# STM32H7B0x register map
File version: 1.3
CPU: CM7 r0p1, little endian, MPU, FPU, 4 interrupt priority bits
Registers are 32-bit, read-write, reset 0x0 unless marked. A register's access mark holds for its fields unless they carry their own. Offsets are from the block's base; [hi:lo] are bit positions; 'fields as' and 'values as' point back to an identical list.

## RCC (part 1 of 3) — Reset and clock control
Base 0x58024400
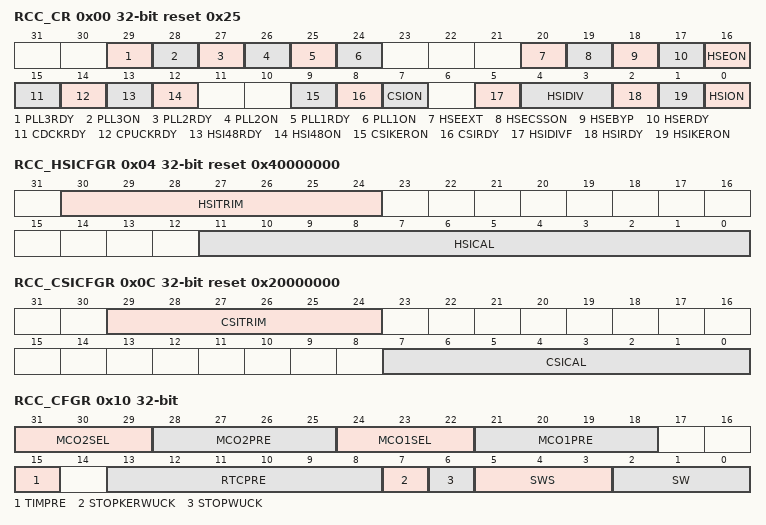
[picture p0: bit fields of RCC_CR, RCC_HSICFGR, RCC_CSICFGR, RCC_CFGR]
0x00 RCC_CR access per field reset 0x25
  [29] PLL3RDY ro — PLL3 clock ready flag Set by hardware to indicate that the PLL3 is locked.
    0=PLL3 unlocked (default after reset); 1=PLL3 locked
  [28] PLL3ON rw — PLL3 enable Set and cleared by software to enable PLL3. Cleared by hardware when entering Stop or Standby mode.
    0=PLL3 OFF (default after reset); 1=PLL3 ON
  [27] PLL2RDY ro — PLL2 clock ready flag Set by hardware to indicate that the PLL2 is locked.
    0=PLL2 unlocked (default after reset); 1=PLL2 locked
  [26] PLL2ON rw — PLL2 enable Set and cleared by software to enable PLL2. Cleared by hardware when entering Stop or Standby mode.
    0=PLL2 OFF (default after reset); 1=PLL2 ON
  [25] PLL1RDY ro — PLL1 clock ready flag Set by hardware to indicate that the PLL1 is locked.
    0=PLL1 unlocked (default after reset); 1=PLL1 locked
  [24] PLL1ON rw — PLL1 enable Set and cleared by software to enable PLL1. Cleared by hardware when entering Stop or Standby mode. Note that the hardware prevents writing this bit to 0, if the PLL1 output is used as the system clock.
    0=PLL1 OFF (default after reset); 1=PLL1 ON
  [20] HSEEXT rw — external high speed clock type in Bypass mode Set and reset by software to select the external clock type (analog or digital). The external clock must be enabled with the HSEON bit to be used by the device. The HSEEXT bit can be written only if the HSE oscillator is disabled.
    0=HSE in analog mode (default after reset); 1=HSE in digital mode
  [19] HSECSSON rw — HSE clock security system enable Set by software to enable clock security system on HSE. This bit is âset onlyâ (disabled by a system reset or when the system enters in Standby mode). When HSECSSON is set, the clock detector is enabled by hardware when the HSE is ready and disabled by hardware if an oscillator failure is detected.
    0=CSS on HSE OFF (clock detector OFF) (default after reset); 1=CSS on HSE ON (clock detector ON if the HSE oscillator is stable, OFF if not)
  [18] HSEBYP rw — HSE clock bypass Set and cleared by software to bypass the oscillator with an external clock. The external clock must be enabled with the HSEON bit to be used by the device. The HSEBYP bit can be written only if the HSE oscillator is disabled.
    0=HSE oscillator not bypassed (default after reset); 1=HSE oscillator bypassed with an external clock
  [17] HSERDY ro — HSE clock ready flag Set by hardware to indicate that the HSE oscillator is stable.
    0=HSE clock is not ready (default after reset); 1=HSE clock is ready
  [16] HSEON rw — HSE clock enable Set and cleared by software. Cleared by hardware to stop the HSE when entering Stop or Standby mode. This bit cannot be cleared if the HSE is used directly (via SW mux) as system clock, or if the HSE is selected as reference clock for PLL1 with PLL1 enabled (PLL1ON bit set to 1).
    0=HSE is OFF (default after reset); 1=HSE is ON
  [15] CDCKRDY ro — CPU domain clocks ready flag Set by hardware to indicate that the following CPU domain clocks are available: APB1, APB2, AHB bus matrix.
    0=CPU domain clocks are not available (default after reset); 1=CPU domain clocks are available
  [14] CPUCKRDY ro — CPU related clocks ready flag Set by hardware to indicate that the CPU related clocks (CPU, APB3, AXI bus matrix and related memories) are available.
    0=CPU related clocks are not available (default after reset); 1=CPU related clocks are available
  [13] HSI48RDY ro — HSI48 clock ready flag Set by hardware to indicate that the HSI48 oscillator is stable.
    0=HSI48 clock is not ready (default after reset); 1=HSI48 clock is ready
  [12] HSI48ON rw — HSI48 clock enable Set by software and cleared by software or by the hardware when the system enters to Stop or Standby mode.
    0=HSI48 is OFF (default after reset); 1=HSI48 is ON
  [9] CSIKERON rw — CSI clock enable in Stop mode Set and reset by software to force the CSI to ON, even in Stop mode, in order to be quickly available as kernel clock for some peripherals. This bit has no effect on the value of CSION.
    0=no effect on CSI (default after reset); 1=CSI is forced to ON even in Stop mode
  [8] CSIRDY ro — CSI clock ready flag Set by hardware to indicate that the CSI oscillator is stable. This bit is activated only if the RC is enabled by CSION (it is not activated if the CSI is enabled by CSIKERON or by a peripheral request).
    0=CSI clock is not ready (default after reset); 1=CSI clock is ready
  [7] CSION rw — CSI clock enable Set and reset by software to enable/disable CSI clock for system and/or peripheral. Set by hardware to force the CSI to ON when the system leaves Stop mode, if STOPWUCK = 1 or STOPKERWUCK = 1. This bit cannot be cleared if the CSI is used directly (via SW mux) as system clock, or if the CSI is selected as reference clock for PLL1 with PLL1 enabled (PLL1ON bit set to 1).
    0=CSI is OFF (default after reset); 1=CSI is ON
  [5] HSIDIVF ro — HSI divider flag Set and reset by hardware. As a write operation to HSIDIV has not an immediate effect on the frequency, this flag indicates the current status of the HSI divider. HSIDIVF goes immediately to 0 when HSIDIV value is changed, and is set back to 1 when the output frequency matches the value programmed into HSIDIV. clock setting is completed)
    0=new division ratio not yet propagated to hsi(_ker)_ck (default after reset); 1=hsi(_ker)_ck clock frequency reflects the new HSIDIV value (default register value when the
  [4:3] HSIDIV rw — HSI clock divider Set and reset by software. These bits allow selecting a division ratio in order to configure the wanted HSI clock frequency. The HSIDIV cannot be changed if the HSI is selected as reference clock for at least one enabled PLL (PLLxON bit set to 1). In that case, the new HSIDIV value is ignored.
    0=division by 1, hsi(_ker)_ck = 64 MHz (default after reset); 1=division by 2, hsi(_ker)_ck = 32 MHz; 2=division by 4, hsi(_ker)_ck = 16 MHz; 3=division by 8, hsi(_ker)_ck = 8 MHz
  [2] HSIRDY ro — HSI clock ready flag Set by hardware to indicate that the HSI oscillator is stable.
    0=HSI clock is not ready (default after reset); 1=HSI clock is ready
  [1] HSIKERON rw — HSI clock enable in Stop mode Set and reset by software to force the HSI to ON, even in Stop mode, in order to be quickly available as kernel clock for peripherals. This bit has no effect on the value of HSION.
    0=no effect on HSI (default after reset); 1=HSI is forced to ON even in Stop mode
  [0] HSION rw — HSI clock enable Set and cleared by software. Set by hardware to force the HSI to ON when the product leaves Stop mode, if STOPWUCK = 0 or STOPKERWUCK = 0. Set by hardware to force the HSI to ON when the product leaves Standby mode or in case of a failure of the HSE which is used as the system clock source. This bit cannot be cleared if the HSI is used directly (via SW mux) as system clock, or if the HSI is selected as reference clock for PLL1 with PLL1 enabled (PLL1ON bit set to 1).
    0=HSI is OFF; 1=HSI is ON (default after reset)
0x04 RCC_HSICFGR access per field reset 0x40000000 (reset mask 0xFFFFF000) — RCC HSI calibration register
  [30:24] HSITRIM rw — HSI clock trimming Set by software to adjust calibration. HSITRIM field is added to the engineering option bytes loaded during reset phase (FLASH_HSI_opt) in order to form the calibration trimming value. HSICALÂ =Â HSITRIMÂ +Â FLASH_HSI_opt. Note: The reset value of the field is 0x40.
  [11:0] HSICAL ro — HSI clock calibration Set by hardware by option byte loading during system reset nreset. Adjusted by software through trimming bits HSITRIM. This field represents the sum of engineering option byte calibration value and HSITRIM bits value.
0x08 RCC_CRRCR ro (reset mask 0xFFFFF000) — RCC clock recovery RC register
  [9:0] HSI48CAL — Internal RC 48 MHz clock calibration Set by hardware by option byte loading during system reset nreset. Read-only.
0x0C RCC_CSICFGR access per field reset 0x20000000 (reset mask 0xFFFFF000) — RCC CSI calibration register
  [29:24] CSITRIM rw — CSI clock trimming Set by software to adjust calibration. CSITRIM field is added to the engineering option bytes loaded during reset phase (FLASH_CSI_opt) in order to form the calibration trimming value. CSICALÂ =Â CSITRIMÂ +Â FLASH_CSI_opt. Note: The reset value of the field is 0x20.
  [7:0] CSICAL ro — CSI clock calibration Set by hardware by option byte loading during system reset nreset. Adjusted by software through trimming bits CSITRIM. This field represents the sum of engineering option byte calibration value and CSITRIM bits value.
0x10 RCC_CFGR access per field
  [31:29] MCO2SEL rw — microcontroller clock output 2 Set and cleared by software. Clock source selection may generate glitches on MCO2. It is highly recommended to configure these bits only after reset, before enabling the external oscillators and the PLLs. others: reserved
    0=system clock selected (sys_ck) (default after reset); 1=PLL2 oscillator clock selected (pll2_p_ck); 2=HSE clock selected (hse_ck); 3=PLL1 clock selected (pll1_p_ck); 4=CSI clock selected (csi_ck); 5=LSI clock selected (lsi_ck)
  [28:25] MCO2PRE rw — MCO2 prescaler Set and cleared by software to configure the prescaler of the MCO2. Modification of this prescaler may generate glitches on MCO2. It is highly recommended to change this prescaler only after reset, before enabling the external oscillators and the PLLs. ...
    0=prescaler disabled (default after reset); 1=division by 1 (bypass); 2=division by 2; 3=division by 3; 4=division by 4; 15=division by 15
  [24:22] MCO1SEL rw — Microcontroller clock output 1 Set and cleared by software. Clock source selection may generate glitches on MCO1. It is highly recommended to configure these bits only after reset, before enabling the external oscillators and the PLLs. others: reserved
    0=HSI clock selected (hsi_ck) (default after reset); 1=LSE oscillator clock selected (lse_ck); 2=HSE clock selected (hse_ck); 3=PLL1 clock selected (pll1_q_ck); 4=HSI48 clock selected (hsi48_ck)
  [21:18] MCO1PRE rw — MCO1 prescaler Set and cleared by software to configure the prescaler of the MCO1. Modification of this prescaler may generate glitches on MCO1. It is highly recommended to change this prescaler only after reset, before enabling the external oscillators and the PLLs. ...
    values as MCO2PRE
  [15] TIMPRE rw — timers clocks prescaler selection This bit is set and reset by software to control the clock frequency of all the timers connected to APB1 and APB2 domains. Refer to for more details.
    0=The timers kernel clock is equal to rcc_hclk1 if CDPPRE1 or CDPPRE2 corresponds to a division by 1 or 2, else it is equal to 2 x Frcc_pclk1 or 2 x Frcc_pclk2 (default after reset); 1=The timers kernel clock is equal to 2 x Frcc_pclk1 or 2 x Frcc_pclk2 if CDPPRE1 or CDPPRE2 corresponds to a division by 1, 2or 4, else it is equal to 4 x Frcc_pclk1 or 4 x Frcc_pclk2
  [13:8] RTCPRE rw — HSE division factor for RTC clock Set and cleared by software to divide the HSE to generate a clock for RTC. Caution: The software must set these bits correctly to ensure that the clock supplied to the RTC is lower than 1Â MHz. These bits must be configured if needed before selecting the RTC clock source. ...
    0=no clock (default after reset); 1=no clock; 2=HSE/2; 3=HSE/3; 4=HSE/4; 62=HSE/62; 63=HSE/63
  [7] STOPKERWUCK rw — kernel clock selection after a wake up from system Stop Set and reset by software to select the kernel wakeup clock from system Stop. See for details.
    0=HSI selected as wake up clock from system Stop (default after reset); 1=CSI selected as wake up clock from system Stop
  [6] STOPWUCK rw — system clock selection after a wake up from system Stop Set and reset by software to select the system wakeup clock from system Stop. The selected clock is also used as emergency clock for the clock security system (CSS) on HSE. See for details. STOPWUCK must not be modified when CSS is enabled (by HSECSSON bit) and the system clock is HSE (SWSÂ =Â 10) or a switch on HSE is requested (SWÂ =10).
    values as STOPKERWUCK
  [5:3] SWS ro — system clock switch status Set and reset by hardware to indicate which clock source is used as system clock. others: reserved
    0=HSI used as system clock (hsi_ck) (default after reset); 1=CSI used as system clock (csi_ck); 2=HSE used as system clock (hse_ck); 3=PLL1 used as system clock (pll1_p_ck)
  [2:0] SW rw — system clock and trace clock switch Set and reset by software to select system clock and trace clock sources (sys_ck and traceclk). Set by hardware in order to: force the selection of the HSI or CSI (depending on STOPWUCK selection) when leaving a system Stop mode force the selection of the HSI in case of failure of the HSE when used directly or indirectly as system clock others: reserved
    0=HSI selected as system clock (hsi_ck) (default after reset); 1=CSI selected as system clock (csi_ck); 2=HSE selected as system clock (hse_ck); 3=PLL1 selected as system clock (pll1_p_ck for sys_ck, pll1_r_ck for traceclk)
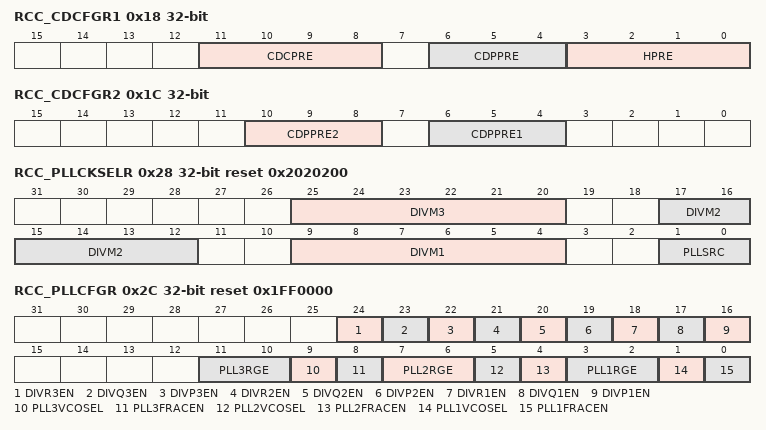
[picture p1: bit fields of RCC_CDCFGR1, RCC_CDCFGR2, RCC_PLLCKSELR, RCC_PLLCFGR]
0x18 RCC_CDCFGR1
  [11:8] CDCPRE — CPU domain core prescaler Set and reset by software to control the CPU domain CPU clock division factor. Changing this division ratio has an impact on the frequency of the CPU clock and all bus matrix clocks. After changing this prescaler value, it takes up to 16 periods of the slowest APB clock before the new division ratio is taken into account. The application can check if the new division factor is taken into account by reading back this register. 0xxx: sys_ck not divided (default after reset)
    8=sys_ck divided by 2; 9=sys_ck divided by 4; 10=sys_ck divided by 8; 11=sys_ck divided by 16; 12=sys_ck divided by 64; 13=sys_ck divided by 128; 14=sys_ck divided by 256; 15=sys_ck divided by 512
  [6:4] CDPPRE — CPU domain APB3 prescaler Set and reset by software to control the division factor of rcc_pclk3. The clock is divided by the new prescaler factor from 1 to 16 cycles of rcc_hclk3 after CDPPRE write. 0xx: rcc_pclk3 = rcc_hclk3 (default after reset)
    4=rcc_pclk3 = rcc_hclk3 / 2; 5=rcc_pclk3 = rcc_hclk3 / 4; 6=rcc_pclk3 = rcc_hclk3 / 8; 7=rcc_pclk3 = rcc_hclk3 / 16
  [3:0] HPRE — CPU domain AHB prescaler Set and reset by software to control the division factor of rcc_hclk3 and rcc_aclk. Changing this division ratio has an impact on the frequency of all bus matrix clocks. 0xxx: rcc_hclk3 = sys_cdcpre_ck (default after reset) Note: The clocks are divided by the new prescaler factor from1 to 16 periods of the slowest APB clock among rcc_pclk[4:1] after HPRE update. Note: Note also that rcc_hclk3 = rcc_aclk.
    8=rcc_hclk3 = sys_cdcpre_ck / 2; 9=rcc_hclk3 = sys_cdcpre_ck / 4; 10=rcc_hclk3 = sys_cdcpre_ck / 8; 11=rcc_hclk3 = sys_cdcpre_ck / 16; 12=rcc_hclk3 = sys_cdcpre_ck / 64; 13=rcc_hclk3 = sys_cdcpre_ck / 128; 14=rcc_hclk3 = sys_cdcpre_ck / 256; 15=rcc_hclk3 = sys_cdcpre_ck / 512
0x1C RCC_CDCFGR2
  [10:8] CDPPRE2 — CPU domain APB2 prescaler Set and reset by software to control the CPU domain APB2 clock division factor. The clock is divided by the new prescaler factor from 1 to 16 cycles of rcc_hclk1 after CDPPRE2 write. 0xx: rcc_pclk2 = rcc_hclk1 (default after reset)
    4=rcc_pclk2 = rcc_hclk1 / 2; 5=rcc_pclk2 = rcc_hclk1 / 4; 6=rcc_pclk2 = rcc_hclk1 / 8; 7=rcc_pclk2 = rcc_hclk1 / 16
  [6:4] CDPPRE1 — CPU domain APB1 prescaler Set and reset by software to control the CPU domain APB1 clock division factor. The clock is divided by the new prescaler factor from 1 to 16 cycles of rcc_hclk1 after CDPPRE1 write. 0xx: rcc_pclk1 = rcc_hclk1 (default after reset)
    4=rcc_pclk1 = rcc_hclk1 / 2; 5=rcc_pclk1 = rcc_hclk1 / 4; 6=rcc_pclk1 = rcc_hclk1 / 8; 7=rcc_pclk1 = rcc_hclk1 / 16
0x20 RCC_SRDCFGR
  [6:4] SRDPPRE — SmartRun domain APB4 prescaler Set and reset by software to control the SmartRun domain APB4 clock division factor. The clock is divided by the new prescaler factor from 1 to 16 cycles of rcc_hclk4 after SRDPPRE write. 0xx: rcc_pclk4 = rcc_hclk4 (default after reset)
    4=rcc_pclk4 = rcc_hclk4 / 2; 5=rcc_pclk4 = rcc_hclk4 / 4; 6=rcc_pclk4 = rcc_hclk4 / 8; 7=rcc_pclk4 = rcc_hclk4 / 16
0x28 RCC_PLLCKSELR reset 0x2020200
  [25:20] DIVM3 — prescaler for PLL3 Set and cleared by software to configure the prescaler of the PLL3. The hardware does not allow any modification of this prescaler when PLL3 is enabled (PLL3ONÂ =Â 1). In order to save power when PLL3 is not used, the value of DIVM3 must be set to 0. ... ...
    0=prescaler disabled (default after reset); 1=division by 1 (bypass); 2=division by 2; 3=division by 3; 32=division by 32 (default after reset); 63=division by 63
  [17:12] DIVM2 — prescaler for PLL2 Set and cleared by software to configure the prescaler of the PLL2. The hardware does not allow any modification of this prescaler when PLL2 is enabled (PLL2ONÂ =Â 1). In order to save power when PLL2 is not used, the value of DIVM2 must be set to 0. ... ...
    0=prescaler disabled; 1=division by 1 (bypass); 2=division by 2; 3=division by 3; 32=division by 32 (default after reset); 63=division by 63
  [9:4] DIVM1 — prescaler for PLL1 Set and cleared by software to configure the prescaler of the PLL1. The hardware does not allow any modification of this prescaler when PLL1 is enabled (PLL1ONÂ =Â 1). In order to save power when PLL1 is not used, the value of DIVM1 must be set to 0. ... ...
    values as DIVM2
  [1:0] PLLSRC — DIVMx and PLLs clock source selection Set and reset by software to select the PLL clock source. These bits can be written only when all PLLs are disabled. In order to save power, when no PLL is used, the value of PLLSRC must be set to '11â.
    0=HSI selected as PLL clock (hsi_ck) (default after reset); 1=CSI selected as PLL clock (csi_ck); 2=HSE selected as PLL clock (hse_ck); 3=no clock send to DIVMx divider and PLLs
0x2C RCC_PLLCFGR reset 0x1FF0000
  [24] DIVR3EN — PLL3 DIVR divider output enable Set and reset by software to enable the pll3_r_ck output of the PLL3. To save power, DIVR3EN and DIVR3 bits must be set to 0 when the pll3_r_ck is not used. This bit can be written only when the PLL3 is disabled (PLL3ON = 0 and PLL3RDY = 0).
    0=pll3_r_ck output disabled; 1=pll3_r_ck output enabled (default after reset)
  [23] DIVQ3EN — PLL3 DIVQ divider output enable Set and reset by software to enable the pll3_q_ck output of the PLL3. To save power, DIVR3EN and DIVR3 bits must be set to 0 when the pll3_r_ck is not used. This bit can be written only when the PLL3 is disabled (PLL3ON = 0 and PLL3RDY = 0).
    0=pll3_q_ck output disabled; 1=pll3_q_ck output enabled (default after reset)
  [22] DIVP3EN — PLL3 DIVP divider output enable Set and reset by software to enable the pll3_p_ck output of the PLL3. This bit can be written only when the PLL3 is disabled (PLL3ON = 0 and PLL3RDY = 0). To save power, DIVR3EN and DIVR3 bits must be set to 0 when the pll3_r_ck is not used.
    0=pll3_p_ck output disabled; 1=pll3_p_ck output enabled (default after reset)
  [21] DIVR2EN — PLL2 DIVR divider output enable Set and reset by software to enable the pll2_r_ck output of the PLL2. To save power, DIVR3EN and DIVR3 bits must be set to 0 when the pll3_r_ck is not used. This bit can be written only when the PLL2 is disabled (PLL2ON = 0 and PLL2RDY = 0).
    0=pll2_r_ck output disabled; 1=pll2_r_ck output enabled (default after reset)
  [20] DIVQ2EN — PLL2 DIVQ divider output enable Set and reset by software to enable the pll2_q_ck output of the PLL2. To save power, DIVR3EN and DIVR3 bits must be set to 0 when the pll3_r_ck is not used. This bit can be written only when the PLL2 is disabled (PLL2ON = 0 and PLL2RDY = 0).
    0=pll2_q_ck output disabled; 1=pll2_q_ck output enabled (default after reset)
  [19] DIVP2EN — PLL2 DIVP divider output enable Set and reset by software to enable the pll2_p_ck output of the PLL2. This bit can be written only when the PLL2 is disabled (PLL2ON = 0 and PLL2RDY = 0). To save power, DIVR3EN and DIVR3 bits must be set to 0 when the pll3_r_ck is not used.
    0=pll2_p_ck output disabled; 1=pll2_p_ck output enabled (default after reset)
  [18] DIVR1EN — PLL1 DIVR divider output enable Set and reset by software to enable the pll1_r_ck output of the PLL1. To save power, DIVR3EN and DIVR3 bits must be set to 0 when the pll3_r_ck is not used. This bit can be written only when the PLL1 is disabled (PLL1ON = 0 and PLL1RDY = 0).
    0=pll1_r_ck output disabled; 1=pll1_r_ck output enabled (default after reset)
  [17] DIVQ1EN — PLL1 DIVQ divider output enable Set and reset by software to enable the pll1_q_ck output of the PLL1. In order to save power, when the pll1_q_ck output of the PLL1 is not used, the pll1_q_ck must be disabled. This bit can be written only when the PLL1 is disabled (PLL1ON = 0 and PLL1RDY = 0).
    0=pll1_q_ck output disabled; 1=pll1_q_ck output enabled (default after reset)
  [16] DIVP1EN — PLL1 DIVP divider output enable Set and reset by software to enable the pll1_p_ck output of the PLL1. This bit can be written only when the PLL1 is disabled (PLL1ON = 0 and PLL1RDY = 0). In order to save power, when the pll1_p_ck output of the PLL1 is not used, the pll1_p_ck must be disabled.
    0=pll1_p_ck output disabled; 1=pll1_p_ck output enabled (default after reset)
  [11:10] PLL3RGE — PLL3 input frequency range Set and reset by software to select the proper reference frequency range used for PLL3. These bits must be written before enabling the PLL3.
    0=PLL3 input (ref3_ck) clock range frequency between 1 and 2 MHz (default after reset); 1=PLL3 input (ref3_ck) clock range frequency between 2 and 4 MHz; 2=PLL3 input (ref3_ck) clock range frequency between 4 and 8 MHz; 3=PLL3 input (ref3_ck) clock range frequency between 8 and 16 MHz
  [9] PLL3VCOSEL — PLL3 VCO selection Set and reset by software to select the proper VCO frequency range used for PLL3. This bit must be written before enabling the PLL3.
    0=wide VCO range 128 to 560 MHz (default after reset); 1=medium VCO range 150 to 420 MHz
  [8] PLL3FRACEN — PLL3 fractional latch enable Set and reset by software to latch the content of FRACN3 into the sigma-delta modulator. In order to latch the FRACN3 value into the sigma-delta modulator, PLL3FRACEN must be set to 0, then set to 1. The transition 0 to 1 transfers the content of FRACN3 into the modulator. Refer to for additional information.
  [7:6] PLL2RGE — PLL2 input frequency range Set and reset by software to select the proper reference frequency range used for PLL2. These bits must be written before enabling the PLL2.
    0=PLL2 input (ref2_ck) clock range frequency between 1 and 2 MHz (default after reset); 1=PLL2 input (ref2_ck) clock range frequency between 2 and 4 MHz; 2=PLL2 input (ref2_ck) clock range frequency between 4 and 8 MHz; 3=PLL2 input (ref2_ck) clock range frequency between 8 and 16 MHz
  [5] PLL2VCOSEL — PLL2 VCO selection Set and reset by software to select the proper VCO frequency range used for PLL2. This bit must be written before enabling the PLL2.
    values as PLL3VCOSEL
  [4] PLL2FRACEN — PLL2 fractional latch enable Set and reset by software to latch the content of FRACN2 into the sigma-delta modulator. In order to latch the FRACN2 value into the sigma-delta modulator, PLL2FRACEN must be set to 0, then set to 1. The transition 0 to 1 transfers the content of FRACN2 into the modulator. Refer to for additional information.
  [3:2] PLL1RGE — PLL1 input frequency range Set and reset by software to select the proper reference frequency range used for PLL1. This bit must be written before enabling the PLL1.
    0=PLL1 input (ref1_ck) clock range frequency between 1 and 2 MHz (default after reset); 1=PLL1 input (ref1_ck) clock range frequency between 2 and 4 MHz; 2=PLL1 input (ref1_ck) clock range frequency between 4 and 8 MHz; 3=PLL1 input (ref1_ck) clock range frequency between 8 and 16 MHz
  [1] PLL1VCOSEL — PLL1 VCO selection Set and reset by software to select the proper VCO frequency range used for PLL1. These bits must be written before enabling the PLL1.
    0=wide VCO range from 128 to 560 MHz (default after reset); 1=medium VCO range from 150 to 420 MHz
  [0] PLL1FRACEN — PLL1 fractional latch enable Set and reset by software to latch the content of FRACN1 into the sigma-delta modulator. In order to latch the FRACN1 value into the sigma-delta modulator, PLL1FRACEN must be set to 0, then set to 1. The transition 0 to 1 transfers the content of FRACN1 into the modulator. Refer to for additional information.
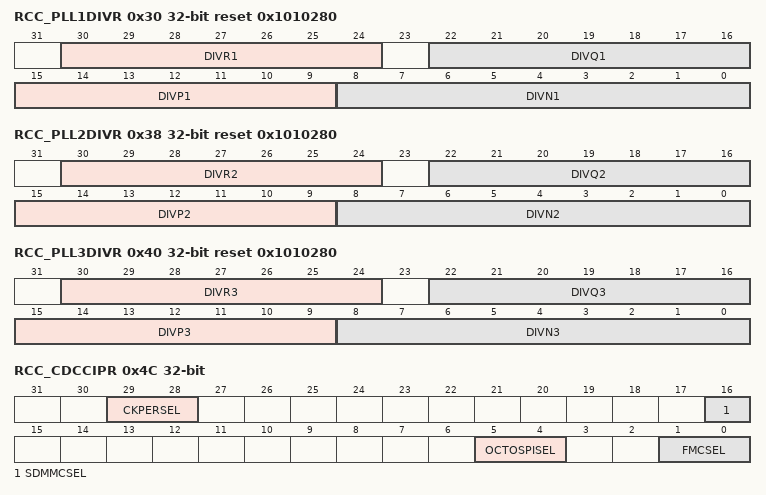
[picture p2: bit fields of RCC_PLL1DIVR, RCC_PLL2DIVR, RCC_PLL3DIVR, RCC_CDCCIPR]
0x30 RCC_PLL1DIVR reset 0x1010280
  [30:24] DIVR1 — PLL1 DIVR division factor Set and reset by software to control the frequency of the pll1_r_ck clock. These bits can be written only when the PLL1 is disabled (PLL1ON = 0 and PLL1RDY = 0). ...
    0=pll1_r_ck = vco1_ck; 1=pll1_r_ck = vco1_ck / 2 (default after reset); 2=pll1_r_ck = vco1_ck / 3; 3=pll1_r_ck = vco1_ck / 4; 127=pll1_r_ck = vco1_ck / 128
  [22:16] DIVQ1 — PLL1 DIVQ division factor Set and reset by software to control the frequency of the pll1_q_ck clock. These bits can be written only when the PLL1 is disabled (PLL1ON = 0 and PLL1RDY = 0). ...
    0=pll1_q_ck = vco1_ck; 1=pll1_q_ck = vco1_ck / 2 (default after reset); 2=pll1_q_ck = vco1_ck / 3; 3=pll1_q_ck = vco1_ck / 4; 127=pll1_q_ck = vco1_ck / 128
  [15:9] DIVP1 — PLL1 DIVP division factor Set and reset by software to control the frequency of the pll1_p_ck clock. These bits can be written only when the PLL1 is disabled (PLL1ON = 0 and PLL1RDY = 0). Note that odd division factors are not allowed. ...
    0=not allowed; 1=pll1_p_ck = vco1_ck / 2 (default after reset); 2=not allowed; 3=pll1_p_ck = vco1_ck / 4; 127=pll1_p_ck = vco1_ck / 128
  [8:0] DIVN1 — multiplication factor for PLL1 VCO Set and reset by software to control the multiplication factor of the VCO. These bits can be written only when the PLL is disabled (PLL1ON = PLL1RDY = 0). ..........: not used ... ... Others: wrong configurations The software must set correctly these bits to insure that the VCO output frequency is between its valid frequency range, that is: 128 to 560Â MHz if PLL1VCOSEL = 0 150 to 420Â MHz if PLL1VCOSEL = 1 VCO output frequency = Fref1_ck x DIVN1, when fractional value 0 has been loaded into FRACN1, with: DIVN1 between 8 and 420 The input frequency Fref1_ck must be between 1 and 16Â MHz.
    6=wrong configuration; 7=DIVN1 = 8; 128=DIVN1 = 129 (default after reset); 0x1A3=DIVN1 = 420
0x34 RCC_PLL1FRACR
  [15:3] FRACN1 — fractional part of the multiplication factor for PLL1 VCO Set and reset by software to control the fractional part of the multiplication factor of the VCO. These bits can be written at any time, allowing dynamic fine-tuning of the PLL1 VCO. The software must set correctly these bits to insure that the VCO output frequency is between its valid frequency range, that is: 128 to 560Â MHz if PLL1VCOSEL = 0 150 to 420Â MHz if PLL1VCOSEL = 1 VCO output frequency = Fref1_ck x (DIVN1 + (FRACN1 / 213)), with DIVN1 between 8 and 420 FRACN1 can be between 0 and 213- 1 The input frequency Fref1_ck must be between 1 and 16 MHz. To change the FRACN value on-the-fly even if the PLL is enabled, the application must proceed as follows: Set the bit PLL1FRACEN to 0. Write the new fractional value into FRACN1. Set the bit PLL1FRACEN to 1.
0x38 RCC_PLL2DIVR reset 0x1010280
  [30:24] DIVR2 — PLL2 DIVR division factor Set and reset by software to control the frequency of the pll2_r_ck clock. These bits can be written only when the PLL2 is disabled (PLL2ON = PLL2RDY = 0). ...
    0=pll2_r_ck = vco2_ck; 1=pll2_r_ck = vco2_ck / 2 (default after reset); 2=pll2_r_ck = vco2_ck / 3; 3=pll2_r_ck = vco2_ck / 4; 127=pll2_r_ck = vco2_ck / 128
  [22:16] DIVQ2 — PLL2 DIVQ division factor Set and reset by software to control the frequency of the pll2_q_ck clock. These bits can be written only when the PLL2 is disabled (PLL2ON = PLL2RDY = 0). ...
    0=pll2_q_ck = vco2_ck; 1=pll2_q_ck = vco2_ck / 2 (default after reset); 2=pll2_q_ck = vco2_ck / 3; 3=pll2_q_ck = vco2_ck / 4; 127=pll2_q_ck = vco2_ck / 128
  [15:9] DIVP2 — PLL2 DIVP division factor Set and reset by software to control the frequency of the pll2_p_ck clock. These bits can be written only when the PLL2 is disabled (PLL2ON = PLL2RDY = 0). ...
    0=pll2_p_ck = vco2_ck; 1=pll2_p_ck = vco2_ck / 2 (default after reset); 2=pll2_p_ck = vco2_ck / 3; 3=pll2_p_ck = vco2_ck / 4; 127=pll2_p_ck = vco2_ck / 128
  [8:0] DIVN2 — multiplication factor for PLL2 VCO Set and reset by software to control the multiplication factor of the VCO. These bits can be written only when the PLL is disabled (PLL2ON = PLL2RDY = 0). ..........: not used ... ... Others: wrong configurations The software must set correctly these bits to insure that the VCO output frequency is between its valid frequency range, that is: 128 to 560Â MHz if PLL2VCOSEL = 0 150 to 420Â MHz if PLL2VCOSEL = 1 VCO output frequency = Fref2_ck x DIVN2, when fractional value 0 has been loaded into FRACN2, with DIVN2 between 8 and 420 The input frequency Fref2_ck must be between 1 and 16MHz.
    6=wrong configuration; 7=DIVN2 = 8; 128=DIVN2 = 129 (default after reset); 0x1A3=DIVN2 = 420
0x3C RCC_PLL2FRACR
  [15:3] FRACN2 — fractional part of the multiplication factor for PLL2 VCO Set and reset by software to control the fractional part of the multiplication factor of the VCO. These bits can be written at any time, allowing dynamic fine-tuning of the PLL2 VCO. The software must set correctly these bits to insure that the VCO output frequency is between its valid frequency range, that is: 128 to 560Â MHz if PLL2VCOSEL = 0 150 to 420Â MHz if PLL2VCOSEL = 1 VCO output frequency = Fref2_ck x (DIVN2 + (FRACN2 / 213)), with DIVN2 between 8 and 420 FRACN2 can be between 0 and 213 - 1 The input frequency Fref2_ck must be between 1 and 16 MHz. In order to change the FRACN value on-the-fly even if the PLL is enabled, the application must proceed as follows: Set the bit PLL2FRACEN to 0. Write the new fractional value into FRACN2. Set the bit PLL2FRACEN to 1.
0x40 RCC_PLL3DIVR reset 0x1010280
  [30:24] DIVR3 — PLL3 DIVR division factor Set and reset by software to control the frequency of the pll3_r_ck clock. These bits can be written only when the PLL3 is disabled (PLL3ON = PLL3RDY = 0). ...
    0=pll3_r_ck = vco3_ck; 1=pll3_r_ck = vco3_ck / 2 (default after reset); 2=pll3_r_ck = vco3_ck / 3; 3=pll3_r_ck = vco3_ck / 4; 127=pll3_r_ck = vco3_ck / 128
  [22:16] DIVQ3 — PLL3 DIVQ division factor Set and reset by software to control the frequency of the pll3_q_ck clock. These bits can be written only when the PLL3 is disabled (PLL3ON = PLL3RDY = 0). ...
    0=pll3_q_ck = vco3_ck; 1=pll3_q_ck = vco3_ck / 2 (default after reset); 2=pll3_q_ck = vco3_ck / 3; 3=pll3_q_ck = vco3_ck / 4; 127=pll3_q_ck = vco3_ck / 128
  [15:9] DIVP3 — PLL3 DIVP division factor Set and reset by software to control the frequency of the pll3_p_ck clock. These bits can be written only when the PLL3 is disabled (PLL3ON = PLL3RDY = 0). ...
    0=pll3_p_ck = vco3_ck; 1=pll3_p_ck = vco3_ck / 2 (default after reset); 2=pll3_p_ck = vco3_ck / 3; 3=pll3_p_ck = vco3_ck / 4; 127=pll3_p_ck = vco3_ck / 128
  [8:0] DIVN3 — Multiplication factor for PLL3 VCO Set and reset by software to control the multiplication factor of the VCO. These bits can be written only when the PLL is disabled (PLL3ON = PLL3RDY = 0). ...........: not used ... ... Others: wrong configurations The software must set correctly these bits to insure that the VCO output frequency is between its valid frequency range, that is: 128 to 560Â MHz if PLL3VCOSEL = 0 150 to 420Â MHz if PLL3VCOSEL = 1 VCO output frequency = Fref3_ck x DIVN3, when fractional value 0 has been loaded into FRACN3, with: DIVN3 between 8 and 420 The input frequency Fref3_ck must be between 1 and 16MHz
    6=wrong configuration; 7=DIVN3 = 8; 128=DIVN3 = 129 (default after reset); 0x1A3=DIVN3 = 420
0x44 RCC_PLL3FRACR
  [15:3] FRACN3 — fractional part of the multiplication factor for PLL3 VCO Set and reset by software to control the fractional part of the multiplication factor of the VCO. These bits can be written at any time, allowing dynamic fine-tuning of the PLL3 VCO. The software must set correctly these bits to insure that the VCO output frequency is between its valid frequency range, that is: 128 to 560Â MHz if PLL3VCOSEL = 0 150 to 420Â MHz if PLL3VCOSEL = 1 VCO output frequency = Fref3_ck x (DIVN3 + (FRACN3 / 213)), with DIVN3 between 8 and 420 FRACN3 can be between 0 and 213 - 1 The input frequency Fref3_ck must be between 1 and 16 MHz. In order to change the FRACN value on-the-fly even if the PLL is enabled, the application must proceed as follows: Set the bit PLL1FRACEN to 0. Write the new fractional value into FRACN1. Set the bit PLL1FRACEN to 1.
0x4C RCC_CDCCIPR — RCC CPU domain kernel clock configuration register
  [29:28] CKPERSEL — per_ck clock source selection
    0=hsi_ker_ck selected as per_ck clock (default after reset); 1=csi_ker_ck selected as per_ck clock; 2=hse_ck selected as per_ck clock; 3=reserved, the per_ck clock is disabled
  [16] SDMMCSEL — SDMMC kernel clock source selection
    0=pll1_q_ck selected as kernel peripheral clock (default after reset); 1=pll2_r_ck selected as kernel peripheral clock
  [5:4] OCTOSPISEL — OCTOSPI kernel clock source selection
    0=rcc_hclk3 selected as kernel peripheral clock (default after reset); 1=pll1_q_ck selected as kernel peripheral clock; 2=pll2_r_ck selected as kernel peripheral clock; 3=per_ck selected as kernel peripheral clock
  [1:0] FMCSEL — FMC kernel clock source selection
    values as OCTOSPISEL
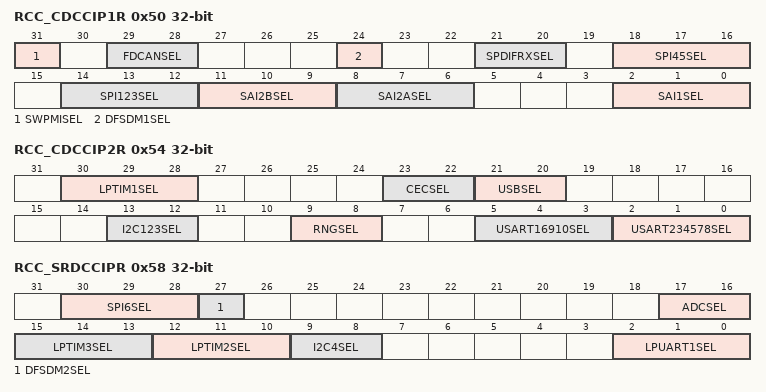
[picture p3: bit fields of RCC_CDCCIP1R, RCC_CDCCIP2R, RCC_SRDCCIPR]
0x50 RCC_CDCCIP1R — RCC CPU domain kernel clock configuration register
  [31] SWPMISEL — SWPMI kernel clock source selection Set and reset by software.
    0=rcc_pclk1 selected as SWPMI kernel clock (default after reset); 1=hsi_ker_ck selected as SWPMI kernel clock
  [29:28] FDCANSEL — FDCAN kernel clock source selection Set and reset by software.
    0=hse_ck clock selected as FDCAN kernel clock (default after reset); 1=pll1_q_ck selected as FDCAN kernel clock; 2=pll2_q_ck selected as FDCAN kernel clock; 3=reserved, the kernel clock is disabled
  [24] DFSDM1SEL — DFSDM1 kernel clock Clk source selection Set and reset by software. Note: the DFSDM1 Aclk clock source selection is done by SAI1SEL (see ).
    0=rcc_pclk2 selected as DFSDM1 Clk kernel clock (default after reset); 1=sys_ck selected as DFSDM1 Clk kernel clock
  [21:20] SPDIFRXSEL — SPDIFRX kernel clock source selection
    0=pll1_q_ck selected as SPDIFRX kernel clock (default after reset); 1=pll2_r_ck selected as SPDIFRX kernel clock; 2=pll3_r_ck selected as SPDIFRX kernel clock; 3=hsi_ker_ck selected as SPDIFRX kernel clock
  [18:16] SPI45SEL — SPI4 and 5 kernel clock source selection Set and reset by software. others: reserved, the kernel clock is disabled
    0=rcc_pclk2 clock selected as kernel clock (default after reset); 1=pll2_q_ck is selected as kernel clock; 2=pll3_q_ck is selected as kernel clock; 3=hsi_ker_ck is selected as kernel clock; 4=csi_ker_ck is selected as kernel clock; 5=hse_ck is selected as kernel clock
  [14:12] SPI123SEL — SPI/I2S1,2 and 3 kernel clock source selection Set and reset by software. If the selected clock is the external clock and this clock is stopped, it is not be possible to switch to another clock. Refer to for additional information. others: reserved, the kernel clock is disabled Note: I2S_CKIN is an external clock taken from a pin.
    0=pll1_q_ck selected as SPI/I2S1,2 and 3 kernel clock (default after reset); 1=pll2_p_ck selected as SPI/I2S1,2 and 3 kernel clock; 2=pll3_p_ck selected as SPI/I2S1,2 and 3 kernel clock; 3=I2S_CKIN selected as SPI/I2S1,2 and 3 kernel clock; 4=per_ck selected as SPI/I2S1,2 and 3 kernel clock
  [11:9] SAI2BSEL — SAI2 kernel clock B source selection Set and reset by software. If the selected clock is the external clock and this clock is stopped, it is not be possible to switch to another clock. Refer to for additional information. others: reserved, the kernel clock is disabled Note: I2S_CKIN is an external clock taken from a pin. spdifrx_symb_ck is the symbol clock generated by the spdifrx (see ).
    0=pll1_q_ck selected as SAI2 kernel clock B (default after reset); 1=pll2_p_ck selected as SAI2 kernel clock B; 2=pll3_p_ck selected as SAI2 kernel clock B; 3=I2S_CKIN selected as SAI2 kernel clock B; 4=per_ck selected as SAI2 kernel clock B; 5=spdifrx_symb_ck selected as SAI2 kernel clock B
  [8:6] SAI2ASEL — SAI2 kernel clock source A selection Set and reset by software. If the selected clock is the external clock and this clock is stopped, it is not be possible to switch to another clock. Refer to for additional information. others: reserved, the kernel clock is disabled Note: I2S_CKIN is an external clock taken from a pin. spdifrx_symb_ck is the symbol clock generated by the SPDIFRX (see ).
    0=pll1_q_ck selected as SAI2 kernel clock A (default after reset); 1=pll2_p_ck selected as SAI2 kernel clock A; 2=pll3_p_ck selected as SAI2 kernel clock A; 3=I2S_CKIN selected as SAI2 kernel clock A; 4=per_ck selected as SAI2 kernel clock A; 5=spdifrx_symb_ck selected as SAI2 kernel clock A
  [2:0] SAI1SEL — SAI1 and DFSDM1 kernel Aclk clock source selection Set and reset by software. If the selected clock is the external clock and this clock is stopped, it isnot be possible to switch to another clock. Refer to for additional information. Note: DFSDM1 clock source selection is done by DFSDM1SEL. others: reserved, the kernel clock is disabled Note: I2S_CKIN is an external clock taken from a pin.
    0=pll1_q_ck selected as SAI1 and DFSDM1 Aclk kernel clock (default after reset); 1=pll2_p_ck selected as SAI1 and DFSDM1 Aclk kernel clock; 2=pll3_p_ck selected as SAI1 and DFSDM1 Aclk kernel clock; 3=I2S_CKIN selected as SAI1 and DFSDM1 Aclk kernel clock; 4=per_ck selected as SAI1 and DFSDM1 Aclk kernel clock
0x54 RCC_CDCCIP2R — RCC CPU domain kernel clock configuration register
  [30:28] LPTIM1SEL — LPTIM1 kernel clock source selection Set and reset by software. others: reserved, the kernel clock is disabled
    0=rcc_pclk1 selected as kernel peripheral clock (default after reset); 1=pll2_p_ck selected as kernel peripheral clock; 2=pll3_r_ck selected as kernel peripheral clock; 3=lse_ck selected as kernel peripheral clock; 4=lsi_ck selected as kernel peripheral clock; 5=per_ck selected as kernel peripheral clock
  [23:22] CECSEL — HDMI-CEC kernel clock source selection Set and reset by software.
    0=lse_ck selected as kernel clock (default after reset); 1=lsi_ck selected as kernel clock; 2=csi_ker_ck divided by 122 selected as kernel clock; 3=reserved, the kernel clock is disabled
  [21:20] USBSEL — USBOTG 1 and 2 kernel clock source selection Set and reset by software.
    0=Disable the kernel clock (default after reset); 1=pll1_q_ck selected as kernel clock; 2=pll3_q_ck selected as kernel clock; 3=hsi48_ck selected as kernel clock
  [13:12] I2C123SEL — I2C1,2,3 kernel clock source selection Set and reset by software.
    0=rcc_pclk1 selected as kernel clock (default after reset); 1=pll3_r_ck selected as kernel clock; 2=hsi_ker_ck selected as kernel clock; 3=csi_ker_ck selected as kernel clock
  [9:8] RNGSEL — RNG kernel clock source selection Set and reset by software.
    0=hsi48_ck selected as kernel clock (default after reset); 1=pll1_q_ck selected as kernel clock; 2=lse_ck selected as kernel clock; 3=lsi_ck selected as kernel clock
  [5:3] USART16910SEL — USART1, 6, 9 and 10 kernel clock source selection Set and reset by software. others: reserved, the kernel clock is disabled
    0=rcc_pclk2 selected as kernel clock (default after reset); 1=pll2_q_ck selected as kernel clock; 2=pll3_q_ck selected as kernel clock; 3=hsi_ker_ck selected as kernel clock; 4=csi_ker_ck selected as kernel clock; 5=lse_ck selected as kernel clock
  [2:0] USART234578SEL — USART2/3, UART4,5, 7 and 8 (APB1) kernel clock source selection Set and reset by software. others: reserved, the kernel clock is disabled
    0=rcc_pclk1 selected as kernel clock (default after reset); 1=pll2_q_ck selected as kernel clock; 2=pll3_q_ck selected as kernel clock; 3=hsi_ker_ck selected as kernel clock; 4=csi_ker_ck selected as kernel clock; 5=lse_ck selected as kernel clock
0x58 RCC_SRDCCIPR — RCC SmartRun domain kernel clock configuration register
  [30:28] SPI6SEL — SPI6 kernel clock source selection Set and reset by software. others: reserved, the kernel clock is disabled
    0=rcc_pclk4 selected as kernel peripheral clock (default after reset); 1=pll2_q_ck selected as kernel peripheral clock; 2=pll3_q_ck selected as kernel peripheral clock; 3=hsi_ker_ck selected as kernel peripheral clock; 4=csi_ker_ck selected as kernel peripheral clock; 5=hse_ck selected as kernel peripheral clock; 6=I2S_CKIN selected as kernel peripheral clock
  [27] DFSDM2SEL — DFSDM2 kernel Clk clock source selection Set and reset by software. Note: The DFSDM2 Aclk clock source selection is done by SPI6SEL (see and ).
    0=rcc_pclk4 selected as DFSDM2 Clk kernel clock (default after reset); 1=sys_ck selected as DFSDM2 Clk kernel clock
  [17:16] ADCSEL — SAR ADC kernel clock source selection Set and reset by software. others: reserved, the kernel clock is disabled
    0=pll2_p_ck selected as kernel peripheral clock (default after reset); 1=pll3_r_ck selected as kernel peripheral clock; 2=per_ck selected as kernel peripheral clock
  [15:13] LPTIM3SEL — LPTIM3 kernel clock source selection Set and reset by software. others: reserved, the kernel clock is disabled
    0=rcc_pclk4 selected as kernel peripheral clock (default after reset); 1=pll2_p_ck selected as kernel peripheral clock; 2=pll3_r_ck selected as kernel peripheral clock; 3=lse_ck selected as kernel peripheral clock; 4=lsi_ck selected as kernel peripheral clock; 5=per_ck selected as kernel peripheral clock
  [12:10] LPTIM2SEL — LPTIM2 kernel clock source selection Set and reset by software. others: reserved, the kernel clock is disabled
    values as LPTIM3SEL
  [9:8] I2C4SEL — I2C4 kernel clock source selection Set and reset by software.
    0=rcc_pclk4 selected as kernel peripheral clock (default after reset); 1=pll3_r_ck selected as kernel peripheral clock; 2=hsi_ker_ck selected as kernel peripheral clock; 3=csi_ker_ck selected as kernel peripheral clock
  [2:0] LPUART1SEL — LPUART1 kernel clock source selection Set and reset by software. others: reserved, the kernel clock is disabled
    0=rcc_pclk4 selected as kernel peripheral clock (default after reset); 1=pll2_q_ck selected as kernel peripheral clock; 2=pll3_q_ck selected as kernel peripheral clock; 3=hsi_ker_ck selected as kernel peripheral clock; 4=csi_ker_ck selected as kernel peripheral clock; 5=lse_ck selected as kernel peripheral clock
